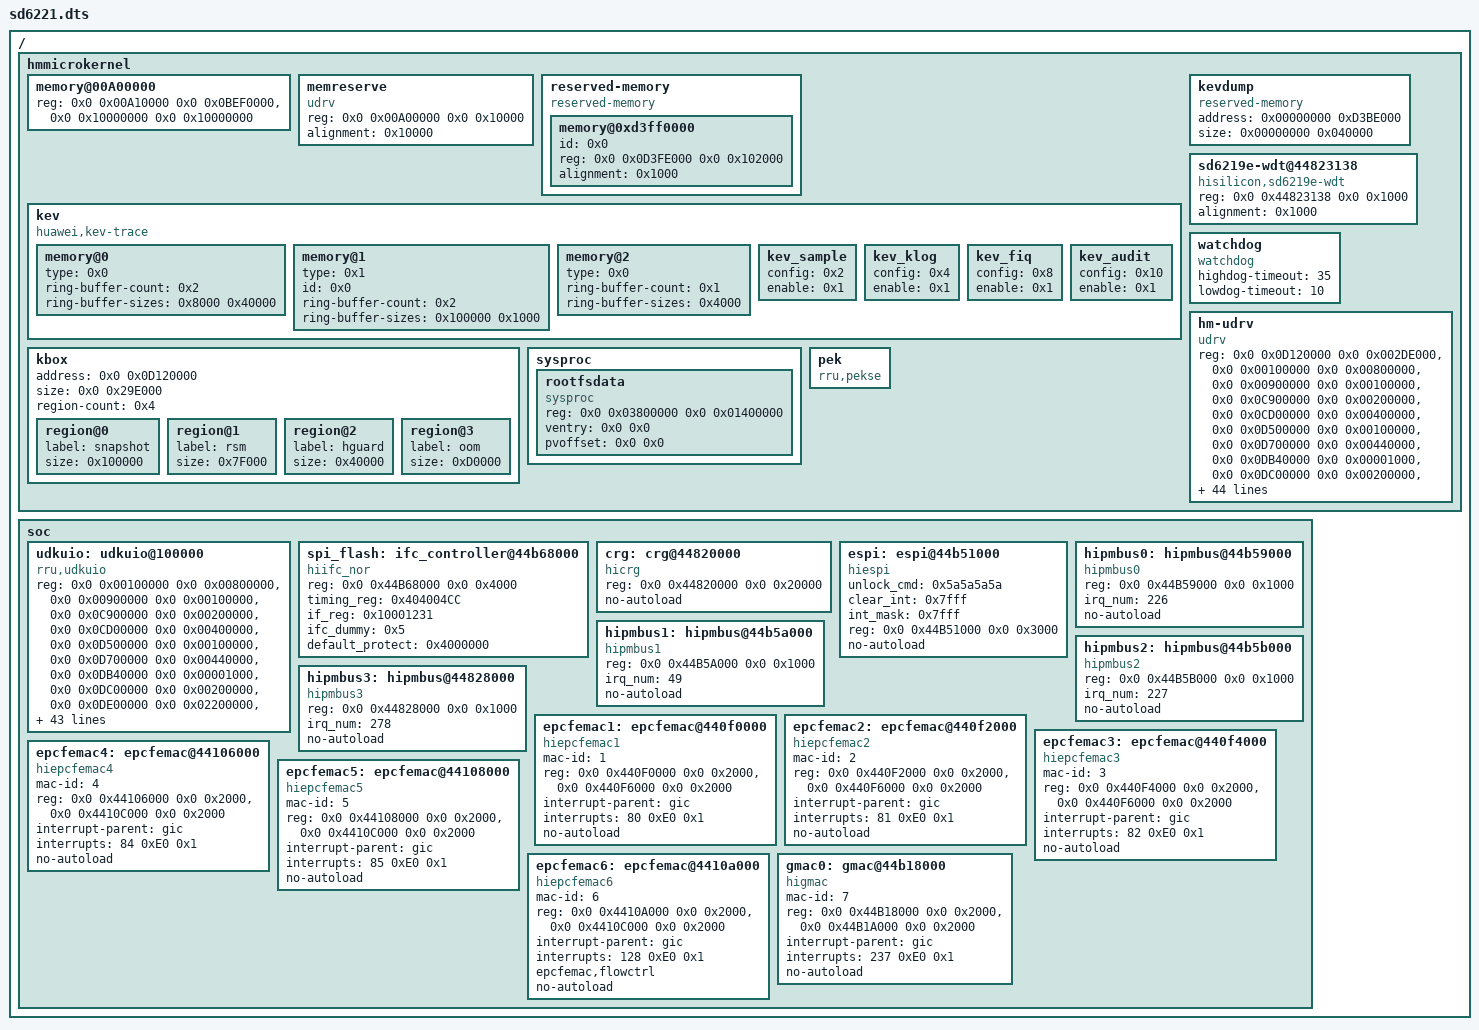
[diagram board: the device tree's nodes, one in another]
/*
 * Device Tree Include file for TIANSHAN SD6221 AAU Board
 */

/dts-v1/;
/memreserve/ 0x00A00000 0x00010000;

/include/ "sd6221.dtsi"

/ {
	hmmicrokernel {
		memory@00A00000 {
			device_type = "memory";
			/* 0xA00000 - 0xA0FFFF is reserved same with rtos (64K) */
			reg = <0x0 0x00A10000 0x0 0x0BEF0000>, /* totally 191M */
			      <0x0 0x10000000 0x0 0x10000000>; /* 256M for linux extern */
		};

		/* we don't support /memreserve/, using a node to reserve memory */
		memreserve {
			#address-cells = <2>;
			#size-cells = <2>;
			compatible = "udrv", "memreserve";

			reg = <0x0 0x00A00000 0x0 0x10000>;
			alignment = <0x10000>;
		};

		reserved-memory {
			compatible = "reserved-memory";
			#address-cells = <2>;
			#size-cells = <2>;
			memory@0xd3ff0000 {
				id = <0x0>;
				reg = <0x0 0x0D3FE000 0x0 0x102000>;
				alignment = <0x1000>;
			};
		};

		kev {
			compatible = "huawei,kev-trace";

			memory@0 {
				type = <0x0>;
				ring-buffer-count = <0x2>;
				/*
				 * ring buffer 0: 32K
				 * ring buffer 1: 256K
				 */
				ring-buffer-sizes = <0x8000 0x40000>;
			};

			memory@1 {
				type = <0x1>; /* reserved memory */
				id = <0x0>;
				ring-buffer-count = <0x2>;
				/*
				 * Only ring buffer DATA sizes. Memory head and ring
				 * buffer heads are not included.
				 * ring buffer 2: 1MB(klog)
				 * ring buffer 3: 4K(fiq)
				 */
				ring-buffer-sizes = <0x100000 0x1000>;
			};

			memory@2 {
				type = <0x0>;
				ring-buffer-count = <0x1>;
				/*
				 * ring buffer 4: 16K(audit)
				 */
				ring-buffer-sizes = <0x4000>;
			};
			kev_sample {
				config = <0x2>;
				enable = <0x1>;
			};
			kev_klog {
				config = <0x4>;
				enable = <0x1>;
			};
			kev_fiq {
				config = <0x8>;
				enable = <0x1>;
			};
			kev_audit {
				config = <0x10>;
				enable = <0x1>;
			};
		};

		kbox {
			address = <0x0 0x0D120000>;
			size = <0x0 0x29E000>;
			region-count= <0x4>;
			region@0 {
				label = "snapshot";
				size = <0x100000>;
			};
			region@1 {
				label = "rsm";
				size = <0x7F000>;
			};
			region@2 {
				label = "hguard";
				size = <0x40000>;
			};
			region@3 {
				label = "oom";
				size = <0xD0000>;
			};
		};

		kevdump {
			compatible = "reserved-memory";
			address = <0x00000000 0xD3BE000>;
			size = <0x00000000 0x040000>;
		};

		sysproc {
			/* Describe board boot param rootfs in top level dts */
			rootfsdata {
				compatible = "sysproc", "rootfs";
				reg = <0x0 0x03800000 0x0 0x01400000>;
				ventry = <0x0 0x0>;
				/* filled by bootloader */
				pvoffset = <0x0 0x0>;
			};
		};

		/* SD6221 CPU use same watchdog as sd6219e */
		sd6219e-wdt@44823138 {
			compatible = "hisilicon,sd6219e-wdt";
			#address-cells = <2>;
			#size-cells = <2>;

			reg = <0x0 0x44823138 0x0 0x1000>;
			alignment = <0x1000>;
		};

		watchdog {
			compatible = "watchdog";
			/* reserve 35s for hguard to take over the watchdog */
			highdog-timeout = <35>;
			/* reserve 10s for subcore to be pulled up*/
			lowdog-timeout = <10>;
		};

		hm-udrv {
			compatible = "udrv";
			reg = <0x0 0x0D120000 0x0 0x002DE000>, /* kbox */
			      <0x0 0x00100000 0x0 0x00800000>, /* BSPLOG */
			      <0x0 0x00900000 0x0 0x00100000>, /* HDF */
			      <0x0 0x0C900000 0x0 0x00200000>, /* HDLCTXRXBD */
			      <0x0 0x0CD00000 0x0 0x00400000>, /* BLACKBOX */
			      <0x0 0x0D500000 0x0 0x00100000>, /* DDR_UEFI_LOG */
			      <0x0 0x0D700000 0x0 0x00440000>, /* DUMP_TS pramdisk */
			      <0x0 0x0DB40000 0x0 0x00001000>, /* DDR_EPC */
			      <0x0 0x0DC00000 0x0 0x00200000>, /* DDR_SRE */
			      <0x0 0x0DE00000 0x0 0x02200000>, /* DDR_DPD */
			      <0x0 0x40000000 0x0 0x00080000>, /* L2M0_DPD */
			      <0x0 0x43800000 0x0 0x00680000>, /* HILINK_SERDES */
			      <0x0 0x44000000 0x0 0x00010000>, /* LOCALBUS */
			      <0x0 0x44020000 0x0 0x00002000>, /* FE(rmii) femac */
			      <0x0 0x44030000 0x0 0x00002000>, /* AHB_SPI */
			      <0x0 0x440D0000 0x0 0x00020000>, /* HDLC */
			      <0x0 0x440F0000 0x0 0x00030000>, /* EPC */
			      <0x0 0x44591000 0x0 0x00001000>, /* MPU_X2X */
			      <0x0 0x44600000 0x0 0x00008000>, /* VP_DEBUG */
			      <0x0 0x44820000 0x0 0x00020000>, /* CRG */
			      <0x0 0x44890000 0x0 0x00001000>, /* LPC */
			      <0x0 0x44892000 0x0 0x00002000>, /* PWR AVS */
			      <0x0 0x44B0F000 0x0 0x00001000>, /* MAIN_SC */
			      <0x0 0x44B18000 0x0 0x00002000>, /* SGMII */
			      <0x0 0x44B1A000 0x0 0x00002000>, /* GMAC */
			      <0x0 0x44B1C000 0x0 0x00001000>, /* IFC_MPU */
			      <0x0 0x44B1D000 0x0 0x00001000>, /* X2H_CVG_MPU */
			      <0x0 0x44B4F000 0x0 0x00002000>, /* TIMER */
			      <0x0 0x44B51000 0x0 0x00003000>, /* ESPI0 */
			      <0x0 0x44B54000 0x0 0x00003000>, /* UART */
			      <0x0 0x44B57000 0x0 0x00001000>, /* DMA */
			      <0x0 0x44B59000 0x0 0x00004000>, /* PMBUS */
			      <0x0 0x44B5D000 0x0 0x00005000>, /* GPIO */
			      <0x0 0x44B62000 0x0 0x00001000>, /* SYSCTRL comm */
			      <0x0 0x44B68000 0x0 0x00004000>, /* IFC */
			      <0x0 0x44B6D000 0x0 0x00001000>, /* LRDXS_DDR */
			      <0x0 0x44B6F000 0x0 0x00001000>, /* DDR_MPU */
			      <0x0 0x44B70000 0x0 0x00010000>, /* DDRC */
			      <0x0 0x44B80000 0x0 0x00001000>, /* IPCM */
			      <0x0 0x44B86000 0x0 0x00001000>, /* SEM */
			      <0x0 0x44B87000 0x0 0x00001000>, /* L2M1_DPD */
			      <0x0 0x44B88000 0x0 0x00005000>, /* GPIO 5-9 */
			      <0x0 0x44B92000 0x0 0x00004000>, /* TIMER 4-11 */
			      <0x0 0x44BEE000 0x0 0x00004000>, /* ETB */
			      <0x0 0x44BF2000 0x0 0x00001000>, /* CPU_SYSCTRL */
			      <0x0 0x45000000 0x0 0x00400000>, /* CPU_DEBUG */
			      <0x0 0x458E0000 0x0 0x00008000>, /* GIC */
			      <0x0 0x48000000 0x0 0x08000000>, /* Local Bus FPGA */
			      <0x0 0x50000000 0x0 0x03000000>, /* UVP */
			      <0x0 0x51880000 0x0 0x00080000>, /* QDMA */
			      <0x0 0x60000000 0x0 0x30000000>, /* ESPI */
			      <0x0 0x90000000 0x0 0x10000000>, /* SFC_M */
			      <0x0 0xB0000000 0x0 0x15800000>; /* ASIC */
		};

		pek {
			compatible = "rru,pekse";
		};
	};

	soc {
		udkuio: udkuio@100000 {
			compatible = "rru,udkuio", "udkuio";
			reg = <0x0 0x00100000 0x0 0x00800000>, /* BSPLOG */
			      <0x0 0x00900000 0x0 0x00100000>, /* HDF */
			      <0x0 0x0C900000 0x0 0x00200000>, /* HDLCTXRXBD */
			      <0x0 0x0CD00000 0x0 0x00400000>, /* BLACKBOX */
			      <0x0 0x0D500000 0x0 0x00100000>, /* DDR_UEFI_LOG */
			      <0x0 0x0D700000 0x0 0x00440000>, /* DUMP_TS pramdisk */
			      <0x0 0x0DB40000 0x0 0x00001000>, /* DDR_EPC */
			      <0x0 0x0DC00000 0x0 0x00200000>, /* DDR_SRE */
			      <0x0 0x0DE00000 0x0 0x02200000>, /* DDR_DPD */
			      <0x0 0x40000000 0x0 0x00080000>, /* L2M0_DPD */
			      <0x0 0x43800000 0x0 0x00680000>, /* HILINK_SERDES */
			      <0x0 0x44000000 0x0 0x00010000>, /* LOCALBUS */
			      <0x0 0x44020000 0x0 0x00002000>, /* FE(rmii) femac */
			      <0x0 0x44030000 0x0 0x00002000>, /* AHB_SPI */
			      <0x0 0x440D0000 0x0 0x00020000>, /* HDLC */
			      <0x0 0x440F0000 0x0 0x00030000>, /* EPC */
			      <0x0 0x44591000 0x0 0x00001000>, /* MPU_X2X */
			      <0x0 0x44600000 0x0 0x00008000>, /* VP_DEBUG */
			      <0x0 0x44820000 0x0 0x00020000>, /* CRG */
			      <0x0 0x44890000 0x0 0x00001000>, /* LPC */
			      <0x0 0x44892000 0x0 0x00002000>, /* PWR AVS */
			      <0x0 0x44B0F000 0x0 0x00001000>, /* MAIN_SC */
			      <0x0 0x44B18000 0x0 0x00002000>, /* SGMII */
			      <0x0 0x44B1A000 0x0 0x00002000>, /* GMAC */
			      <0x0 0x44B1C000 0x0 0x00001000>, /* IFC_MPU */
			      <0x0 0x44B1D000 0x0 0x00001000>, /* X2H_CVG_MPU */
			      <0x0 0x44B4F000 0x0 0x00002000>, /* TIMER */
			      <0x0 0x44B51000 0x0 0x00003000>, /* ESPI0 */
			      <0x0 0x44B54000 0x0 0x00003000>, /* UART */
			      <0x0 0x44B57000 0x0 0x00001000>, /* DMA */
			      <0x0 0x44B59000 0x0 0x00004000>, /* PMBUS */
			      <0x0 0x44B5D000 0x0 0x00005000>, /* GPIO */
			      <0x0 0x44B62000 0x0 0x00001000>, /* SYSCTRL comm */
			      <0x0 0x44B68000 0x0 0x00004000>, /* IFC */
			      <0x0 0x44B6D000 0x0 0x00001000>, /* LRDXS_DDR */
			      <0x0 0x44B6F000 0x0 0x00001000>, /* DDR_MPU */
			      <0x0 0x44B70000 0x0 0x00010000>, /* DDRC */
			      <0x0 0x44B80000 0x0 0x00001000>, /* IPCM */
			      <0x0 0x44B86000 0x0 0x00001000>, /* SEM */
			      <0x0 0x44B87000 0x0 0x00001000>, /* L2M1_DPD */
			      <0x0 0x44B88000 0x0 0x00005000>, /* GPIO 5-9 */
			      <0x0 0x44B92000 0x0 0x00004000>, /* TIMER 4-11 */
			      <0x0 0x44BEE000 0x0 0x00004000>, /* ETB */
			      <0x0 0x44BF2000 0x0 0x00001000>, /* CPU_SYSCTRL */
			      <0x0 0x45000000 0x0 0x00400000>, /* CPU_DEBUG */
			      <0x0 0x458E0000 0x0 0x00008000>, /* GIC */
			      <0x0 0x48000000 0x0 0x08000000>, /* Local Bus FPGA */
			      <0x0 0x50000000 0x0 0x03000000>, /* UVP */
			      <0x0 0x51880000 0x0 0x00080000>, /* QDMA */
			      <0x0 0x60000000 0x0 0x30000000>, /* ESPI */
			      <0x0 0x90000000 0x0 0x10000000>, /* SFC_M */
			      <0x0 0xB0000000 0x0 0x15800000>; /* ASIC */
		};

		spi_flash:ifc_controller@44b68000 {
			compatible = "hiifc_nor";
			reg = <0x0 0x44B68000 0x0 0x4000>;  /* IFC IP Base Adddr , length */
			timing_reg = <0x404004CC>; /* TIMING_CFG REG Default Value */
			if_reg = <0x10001231>;  /* IF_CFG REG Default Value */
			ifc_dummy = <0x5>;  /* IFC Dummy Value */
			status = "okay";
			default_protect = <0x4000000>;
		};

		crg: crg@44820000 {
			compatible = "hicrg";
			reg = <0x0 0x44820000 0x0 0x20000>;
			no-autoload;
		};

		espi: espi@44b51000 {
			compatible = "hiespi";
			unlock_cmd = <0x5a5a5a5a>;
			clear_int = <0x7fff>;
			int_mask = <0x7fff>;
			reg = <0x0 0x44B51000 0x0 0x3000>;
			no-autoload;
		};

		hipmbus0: hipmbus@44b59000 {
			compatible = "hipmbus0";
			reg = <0x0 0x44B59000 0x0 0x1000>;
			irq_num  = <226>;
			no-autoload;
		};

		hipmbus1: hipmbus@44b5a000 {
			compatible = "hipmbus1";
			reg = <0x0 0x44B5A000 0x0 0x1000>;
			irq_num  = <49>;
			no-autoload;
		};

		hipmbus2: hipmbus@44b5b000 {
			compatible = "hipmbus2";
			reg = <0x0 0x44B5B000 0x0 0x1000>;
			irq_num  = <227>;
			no-autoload;
		};

		hipmbus3: hipmbus@44828000 {
			compatible = "hipmbus3";
			reg = <0x0 0x44828000 0x0 0x1000>;
			irq_num  = <278>;
			no-autoload;
		};

		epcfemac1: epcfemac@440f0000 {
			compatible = "hiepcfemac1";
			mac-id = <1>;
			reg = <0x0 0x440F0000 0x0 0x2000>,
			      <0x0 0x440F6000 0x0 0x2000>;
			interrupt-parent = <&gic>;
			interrupts = <80 0xE0 0x1>;
			no-autoload;
		};

		epcfemac2: epcfemac@440f2000 {
			compatible = "hiepcfemac2";
			mac-id = <2>;
			reg = <0x0 0x440F2000 0x0 0x2000>,
			      <0x0 0x440F6000 0x0 0x2000>;
			interrupt-parent = <&gic>;
			interrupts = <81 0xE0 0x1>;
			no-autoload;
		};

		epcfemac3: epcfemac@440f4000 {
			compatible = "hiepcfemac3";
			mac-id = <3>;
			reg = <0x0 0x440F4000 0x0 0x2000>,
			      <0x0 0x440F6000 0x0 0x2000>;
			interrupt-parent = <&gic>;
			interrupts = <82 0xE0 0x1>;
			no-autoload;
		};

		epcfemac4: epcfemac@44106000 {
			compatible = "hiepcfemac4";
			mac-id = <4>;
			reg = <0x0 0x44106000 0x0 0x2000>,
			      <0x0 0x4410C000 0x0 0x2000>;
			interrupt-parent = <&gic>;
			interrupts = <84 0xE0 0x1>;
			no-autoload;
		};

		epcfemac5: epcfemac@44108000 {
			compatible = "hiepcfemac5";
			mac-id = <5>;
			reg = <0x0 0x44108000 0x0 0x2000>,
			      <0x0 0x4410C000 0x0 0x2000>;
			interrupt-parent = <&gic>;
			interrupts = <85 0xE0 0x1>;
			no-autoload;
		};

		epcfemac6: epcfemac@4410a000 {
			compatible = "hiepcfemac6";
			mac-id = <6>;
			reg = <0x0 0x4410A000 0x0 0x2000>,
			      <0x0 0x4410C000 0x0 0x2000>;
			interrupt-parent = <&gic>;
			interrupts = <128 0xE0 0x1>;
			epcfemac,flowctrl;
			no-autoload;
		};

		gmac0: gmac@44b18000 {
			compatible = "higmac";
			mac-id = <7>;
			reg = <0x0 0x44B18000 0x0 0x2000>,
			      <0x0 0x44B1A000 0x0 0x2000>;
			interrupt-parent = <&gic>;
			interrupts = <237 0xE0 0x1>;
			no-autoload;
		};
	};
};
